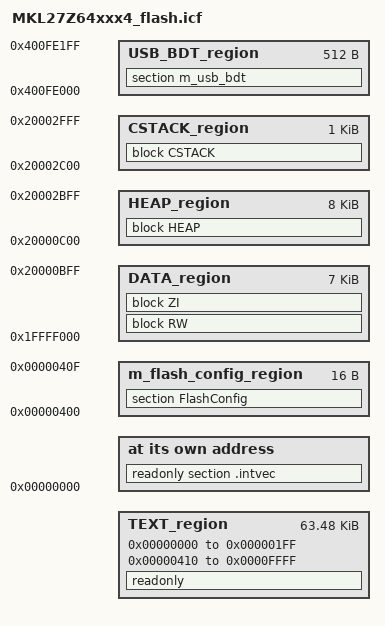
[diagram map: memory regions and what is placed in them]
/*
** ###################################################################
**     Processors:          MKL27Z64VDA4
**                          MKL27Z64VFM4
**                          MKL27Z64VFT4
**                          MKL27Z64VLH4
**                          MKL27Z64VMP4
**
**     Compiler:            IAR ANSI C/C++ Compiler for ARM
**     Reference manual:    KL27P64M48SF2RM, Rev. 1, Sep 2014
**     Version:             rev. 1.4, 2014-09-22
**     Build:               b171205
**
**     Abstract:
**         Linker file for the IAR ANSI C/C++ Compiler for ARM
**
**     The Clear BSD License
**     Copyright 2016 Freescale Semiconductor, Inc.
**     Copyright 2016-2017 NXP
**     All rights reserved.
**
**     Redistribution and use in source and binary forms, with or without
**     modification, are permitted (subject to the limitations in the
**     disclaimer below) provided that the following conditions are met:
**
**     * Redistributions of source code must retain the above copyright
**       notice, this list of conditions and the following disclaimer.
**
**     * Redistributions in binary form must reproduce the above copyright
**       notice, this list of conditions and the following disclaimer in the
**       documentation and/or other materials provided with the distribution.
**
**     * Neither the name of the copyright holder nor the names of its
**       contributors may be used to endorse or promote products derived from
**       this software without specific prior written permission.
**
**     NO EXPRESS OR IMPLIED LICENSES TO ANY PARTY'S PATENT RIGHTS ARE
**     GRANTED BY THIS LICENSE. THIS SOFTWARE IS PROVIDED BY THE COPYRIGHT
**     HOLDERS AND CONTRIBUTORS "AS IS" AND ANY EXPRESS OR IMPLIED
**     WARRANTIES, INCLUDING, BUT NOT LIMITED TO, THE IMPLIED WARRANTIES OF
**     MERCHANTABILITY AND FITNESS FOR A PARTICULAR PURPOSE ARE
**     DISCLAIMED. IN NO EVENT SHALL THE COPYRIGHT HOLDER OR CONTRIBUTORS BE
**     LIABLE FOR ANY DIRECT, INDIRECT, INCIDENTAL, SPECIAL, EXEMPLARY, OR
**     CONSEQUENTIAL DAMAGES (INCLUDING, BUT NOT LIMITED TO, PROCUREMENT OF
**     SUBSTITUTE GOODS OR SERVICES; LOSS OF USE, DATA, OR PROFITS; OR
**     BUSINESS INTERRUPTION) HOWEVER CAUSED AND ON ANY THEORY OF LIABILITY,
**     WHETHER IN CONTRACT, STRICT LIABILITY, OR TORT (INCLUDING NEGLIGENCE
**     OR OTHERWISE) ARISING IN ANY WAY OUT OF THE USE OF THIS SOFTWARE, EVEN
**     IF ADVISED OF THE POSSIBILITY OF SUCH DAMAGE.
**
**     http:                 www.nxp.com
**     mail:                 support@nxp.com
**
** ###################################################################
*/

define symbol m_interrupts_start       = 0x00000000;
define symbol m_interrupts_end         = 0x000001FF;

define symbol m_flash_config_start     = 0x00000400;
define symbol m_flash_config_end       = 0x0000040F;

define symbol m_text_start             = 0x00000410;
define symbol m_text_end               = 0x0000FFFF;

define symbol m_data_start             = 0x1FFFF000;
define symbol m_data_end               = 0x20002FFF;

define symbol m_usb_sram_start         = 0x400FE000;
define symbol m_usb_sram_end           = 0x400FE1FF;

/* USB BDT size */
define symbol usb_bdt_size             = 0x200;
/* Sizes */
if (isdefinedsymbol(__stack_size__)) {
  define symbol __size_cstack__        = __stack_size__;
} else {
  define symbol __size_cstack__        = 0x0400;
}

if (isdefinedsymbol(__heap_size__)) {
  define symbol __size_heap__          = __heap_size__;
} else {
  define symbol __size_heap__          = 0x2000;
}

define memory mem with size = 4G;
define region m_flash_config_region = mem:[from m_flash_config_start to m_flash_config_end];
define region TEXT_region = mem:[from m_interrupts_start to m_interrupts_end]
                          | mem:[from m_text_start to m_text_end];
define region DATA_region = mem:[from m_data_start to m_data_end-__size_cstack__-__size_heap__];
define region HEAP_region = mem:[from m_data_end-__size_cstack__-__size_heap__+1 to m_data_end-__size_cstack__];
define region CSTACK_region = mem:[from m_data_end-__size_cstack__+1 to m_data_end];

define block CSTACK    with alignment = 8, size = __size_cstack__   { };
define block HEAP      with alignment = 8, size = __size_heap__     { };
define block RW        { readwrite };
define block ZI        { zi };

/* regions for USB */
define region USB_BDT_region = mem:[from m_usb_sram_start to m_usb_sram_start + usb_bdt_size - 1];
place in USB_BDT_region                     { section m_usb_bdt };

initialize by copy { readwrite, section .textrw };
do not initialize  { section .noinit, section m_usb_bdt };

place at address mem: m_interrupts_start    { readonly section .intvec };
place in m_flash_config_region              { section FlashConfig };
place in TEXT_region                        { readonly };
place in DATA_region                        { block RW };
place in DATA_region                        { block ZI };
place in HEAP_region                        { block HEAP };
place in CSTACK_region                      { block CSTACK };

define symbol __heap_start__ = start(HEAP_region);
export symbol __size_heap__;
export symbol __heap_start__;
